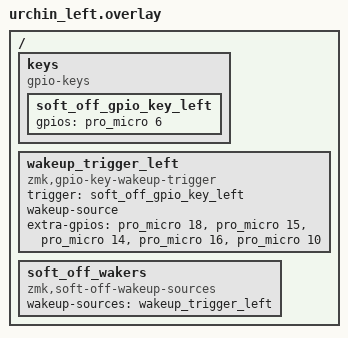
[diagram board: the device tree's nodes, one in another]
/ {
    keys {
        compatible = "gpio-keys";
        soft_off_gpio_key_left: soft_off_gpio_key_left {
            gpios = <&pro_micro 6 (GPIO_ACTIVE_HIGH | GPIO_PULL_DOWN)>;
        };
    };

    wakeup_trigger_left: wakeup_trigger_left {
        compatible = "zmk,gpio-key-wakeup-trigger";
        trigger = <&soft_off_gpio_key_left>;
        wakeup-source;
        
        extra-gpios = 
            <&pro_micro 18 GPIO_ACTIVE_HIGH>,
            <&pro_micro 15 GPIO_ACTIVE_HIGH>,
            <&pro_micro 14 GPIO_ACTIVE_HIGH>,
            <&pro_micro 16 GPIO_ACTIVE_HIGH>,
            <&pro_micro 10 GPIO_ACTIVE_HIGH>;
    };

    soft_off_wakers {
        compatible = "zmk,soft-off-wakeup-sources";
        wakeup-sources = <&wakeup_trigger_left>;
    };
};
